# PIC16LF1779 register map
Vendor: Microchip
Registers are 8-bit, read-write, reset 0x0 unless marked. A register's access mark holds for its fields unless they carry their own. Addresses are absolute, and some are shared; only a register's first bit layout is shown; [hi:lo] are bit positions; {n}, {i} and the like mark numbered series; 'fields as' and 'values as' point back to an identical list.

## amp_opamp_hvpump
{0x50B+4i} OPA{i}NCHS (i=1..4)
  [3:0] NCH
{0x50C+4i} OPA{i}PCHS (i=1..4)
  [3:0] PCH
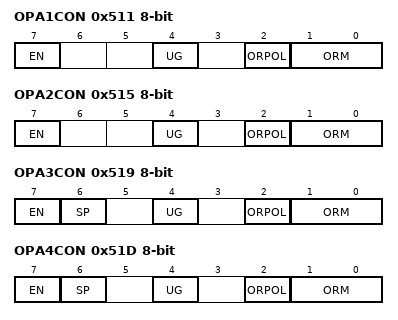
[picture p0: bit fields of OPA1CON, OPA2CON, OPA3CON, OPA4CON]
0x511 OPA1CON
  [7] EN, [4] UG, [2] ORPOL, [1:0] ORM
{0x50E+4i} OPA{i}ORS (i=1..3)
  [4:0] ORS
0x515 OPA2CON
  [7] EN, [4] UG, [2] ORPOL, [1:0] ORM
0x519 OPA3CON
  [7] EN, [6] SP, [4] UG, [2] ORPOL, [1:0] ORM
0x51D OPA4CON
  [7] EN, [6] SP, [4] UG, [2] ORPOL, [1:0] ORM
0x51E OPA4ORS
  [7:0] ORS

## dac_nbit__ctrl
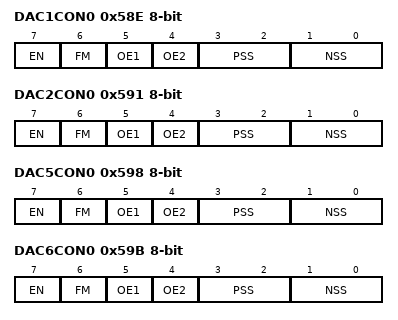
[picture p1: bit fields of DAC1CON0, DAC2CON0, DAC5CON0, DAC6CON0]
0x58E DAC1CON0
  [7] EN, [6] FM, [5] OE1, [4] OE2, [3:2] PSS, [1:0] NSS
0x58F DAC1REFL
  [7:0] REF
0x590 DAC1REFH
  [7:0] REF
0x591 DAC2CON0
  [7] EN, [6] FM, [5] OE1, [4] OE2, [3:2] PSS, [1:0] NSS
0x592 DAC2REFL
  [7:0] REF
0x593 DAC2REFH
  [7:0] REF
0x598 DAC5CON0
  [7] EN, [6] FM, [5] OE1, [4] OE2, [3:2] PSS, [1:0] NSS
0x599 DAC5REFL
  [7:0] REF
0x59A DAC5REFH
  [7:0] REF
0x59B DAC6CON0
  [7] EN, [6] FM, [5] OE1, [4] OE2, [3:2] PSS, [1:0] NSS
0x59C DAC6REFL
  [7:0] REF
0x59D DAC6REFH
  [7:0] REF

## 5bit_DAC_wNSS
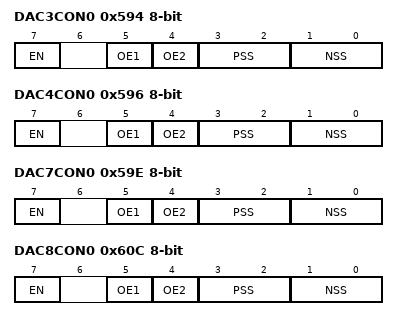
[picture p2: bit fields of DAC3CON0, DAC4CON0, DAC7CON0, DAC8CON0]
0x594 DAC3CON0
  [7] EN, [5] OE1, [4] OE2, [3:2] PSS, [1:0] NSS
0x595 DAC3REF
  [4:0] DACR
0x596 DAC4CON0
  [7] EN, [5] OE1, [4] OE2, [3:2] PSS, [1:0] NSS
0x597 DAC4REF
  [4:0] DACR
0x59E DAC7CON0
  [7] EN, [5] OE1, [4] OE2, [3:2] PSS, [1:0] NSS
0x59F DAC7REF
  [4:0] DACR
0x60C DAC8CON0
  [7] EN, [5] OE1, [4] OE2, [3:2] PSS, [1:0] NSS
0x60D DAC8REF
  [4:0] DACR

## amp_sloperamp_ctrl
0x60E PRG4RTSS
  [3:0] RTSS
0x60F PRG4FTSS
  [3:0] FTSS
0x610 PRG4INS
  [3:0] INS
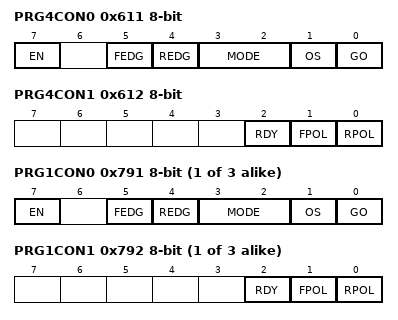
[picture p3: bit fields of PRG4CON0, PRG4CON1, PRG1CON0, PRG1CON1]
0x611 PRG4CON0
  [7] EN, [5] FEDG, [4] REDG, [3:2] MODE, [1] OS, [0] GO
0x612 PRG4CON1
  [2] RDY ro, [1] FPOL, [0] RPOL
0x613 PRG4CON2
  [4:0] ISET
{0x788+6i} PRG{i}RTSS (i=1..3)
  [3:0] RTSS
{0x789+6i} PRG{i}FTSS (i=1..3)
  [3:0] FTSS
{0x78A+6i} PRG{i}INS (i=1..3)
  [3:0] INS
{0x78B+6i} PRG{i}CON0 (i=1..3)
  [7] EN, [5] FEDG, [4] REDG, [3:2] MODE, [1] OS, [0] GO
{0x78C+6i} PRG{i}CON1 (i=1..3)
  [2] RDY ro, [1] FPOL, [0] RPOL
{0x78D+6i} PRG{i}CON2 (i=1..3)
  [4:0] ISET

## pwm_cog
0x68D COG1PHR
  [5:0] PHR
0x68E COG1PHF
  [5:0] PHF
0x68F COG1BLKR
  [5:0] BLKR
0x690 COG1BLKF
  [5:0] BLKF
0x691 COG1DBR
  [5:0] DBR
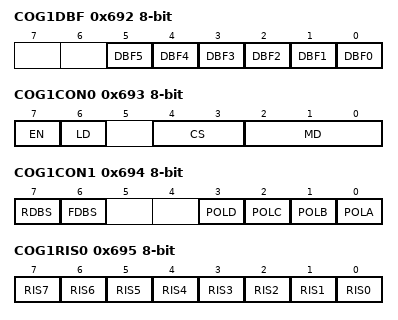
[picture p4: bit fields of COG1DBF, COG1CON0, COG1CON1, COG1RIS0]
0x692 COG1DBF
  [n] DBF{n} (n=0..5)
0x693 COG1CON0
  [7] EN, [6] LD, [4:3] CS, [2:0] MD
0x694 COG1CON1
  [7] RDBS, [6] FDBS, [3] POLD, [2] POLC, [1] POLB, [0] POLA
0x695 COG1RIS0
  [n] RIS{n} (n=0..7)
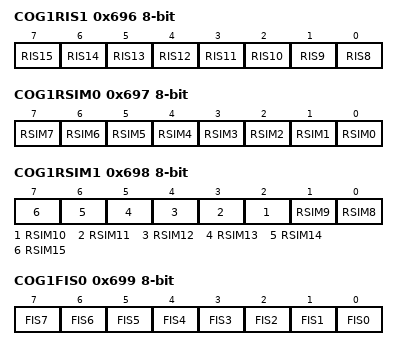
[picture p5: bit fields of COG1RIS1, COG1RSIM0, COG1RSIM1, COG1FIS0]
0x696 COG1RIS1
  [n-8] RIS{n} (n=8..15)
0x697 COG1RSIM0
  [n] RSIM{n} (n=0..7)
0x698 COG1RSIM1
  [n-8] RSIM{n} (n=8..15)
0x699 COG1FIS0
  [n] FIS{n} (n=0..7)
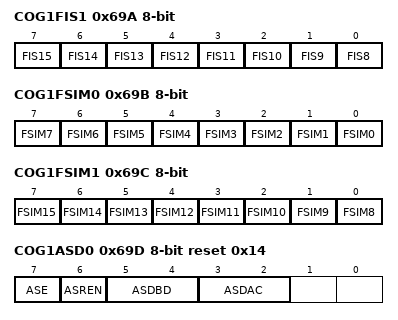
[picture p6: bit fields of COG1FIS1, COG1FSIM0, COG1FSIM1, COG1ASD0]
0x69A COG1FIS1
  [n-8] FIS{n} (n=8..15)
0x69B COG1FSIM0
  [n] FSIM{n} (n=0..7)
0x69C COG1FSIM1
  [n-8] FSIM{n} (n=8..15)
0x69D COG1ASD0 reset 0x14
  [7] ASE, [6] ASREN, [5:4] ASDBD, [3:2] ASDAC
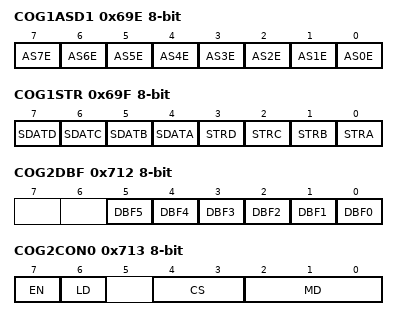
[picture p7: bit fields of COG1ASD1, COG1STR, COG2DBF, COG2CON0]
0x69E COG1ASD1
  [n] AS{n}E (n=0..7)
0x69F COG1STR
  [7] SDATD, [6] SDATC, [5] SDATB, [4] SDATA, [3] STRD, [2] STRC, [1] STRB, [0] STRA
0x70D COG2PHR
  [5:0] PHR
0x70E COG2PHF
  [5:0] PHF
0x70F COG2BLKR
  [5:0] BLKR
0x710 COG2BLKF
  [5:0] BLKF
0x711 COG2DBR
  [5:0] DBR
0x712 COG2DBF
  [n] DBF{n} (n=0..5)
0x713 COG2CON0
  [7] EN, [6] LD, [4:3] CS, [2:0] MD
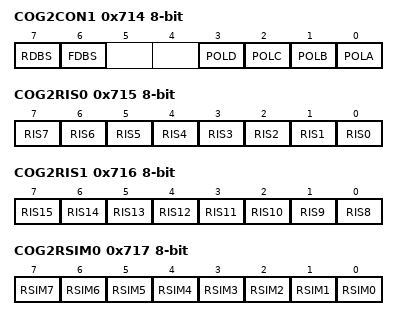
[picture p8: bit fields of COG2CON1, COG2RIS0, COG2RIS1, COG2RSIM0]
0x714 COG2CON1
  [7] RDBS, [6] FDBS, [3] POLD, [2] POLC, [1] POLB, [0] POLA
0x715 COG2RIS0
  [n] RIS{n} (n=0..7)
0x716 COG2RIS1
  [n-8] RIS{n} (n=8..15)
0x717 COG2RSIM0
  [n] RSIM{n} (n=0..7)
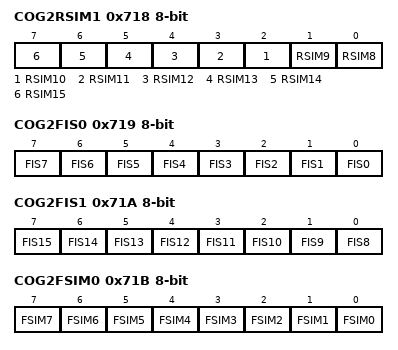
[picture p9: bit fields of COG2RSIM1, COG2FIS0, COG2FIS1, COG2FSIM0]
0x718 COG2RSIM1
  [n-8] RSIM{n} (n=8..15)
0x719 COG2FIS0
  [n] FIS{n} (n=0..7)
0x71A COG2FIS1
  [n-8] FIS{n} (n=8..15)
0x71B COG2FSIM0
  [n] FSIM{n} (n=0..7)
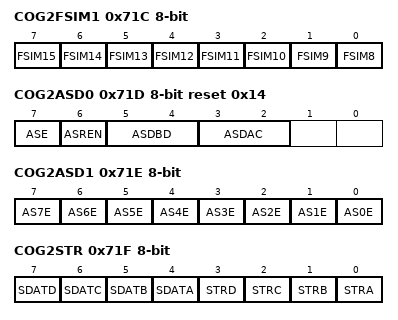
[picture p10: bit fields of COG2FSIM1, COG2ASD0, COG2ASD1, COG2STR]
0x71C COG2FSIM1
  [n-8] FSIM{n} (n=8..15)
0x71D COG2ASD0 reset 0x14
  [7] ASE, [6] ASREN, [5:4] ASDBD, [3:2] ASDAC
0x71E COG2ASD1
  [n] AS{n}E (n=0..7)
0x71F COG2STR
  fields as COG1STR
0x80D COG3PHR
  [5:0] PHR
0x80E COG3PHF
  [5:0] PHF
0x80F COG3BLKR
  [5:0] BLKR
0x810 COG3BLKF
  [5:0] BLKF
0x811 COG3DBR
  [5:0] DBR
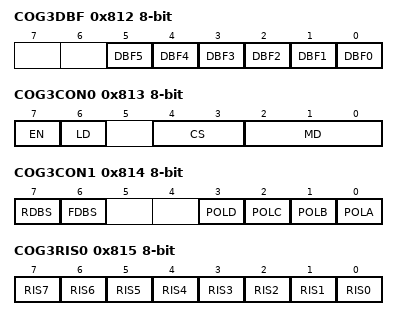
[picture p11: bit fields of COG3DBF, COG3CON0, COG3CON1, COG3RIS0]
0x812 COG3DBF
  [n] DBF{n} (n=0..5)
0x813 COG3CON0
  [7] EN, [6] LD, [4:3] CS, [2:0] MD
0x814 COG3CON1
  [7] RDBS, [6] FDBS, [3] POLD, [2] POLC, [1] POLB, [0] POLA
0x815 COG3RIS0
  [n] RIS{n} (n=0..7)
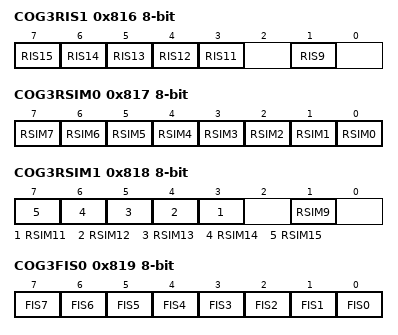
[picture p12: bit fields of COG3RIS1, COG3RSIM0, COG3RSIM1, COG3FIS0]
0x816 COG3RIS1
  [n-8] RIS{n} (n=11..15), [1] RIS9
0x817 COG3RSIM0
  [n] RSIM{n} (n=0..7)
0x818 COG3RSIM1
  [n-8] RSIM{n} (n=11..15), [1] RSIM9
0x819 COG3FIS0
  [n] FIS{n} (n=0..7)
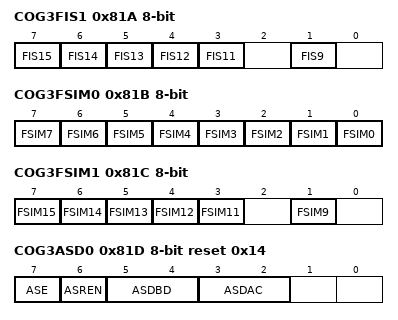
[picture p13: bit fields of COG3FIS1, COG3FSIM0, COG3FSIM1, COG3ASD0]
0x81A COG3FIS1
  [n-8] FIS{n} (n=11..15), [1] FIS9
0x81B COG3FSIM0
  [n] FSIM{n} (n=0..7)
0x81C COG3FSIM1
  [n-8] FSIM{n} (n=11..15), [1] FSIM9
0x81D COG3ASD0 reset 0x14
  [7] ASE, [6] ASREN, [5:4] ASDBD, [3:2] ASDAC
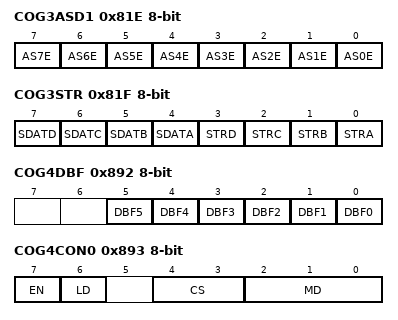
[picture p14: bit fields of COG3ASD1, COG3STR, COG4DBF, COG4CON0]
0x81E COG3ASD1
  [n] AS{n}E (n=0..7)
0x81F COG3STR
  fields as COG1STR
0x88D COG4PHR
  [5:0] PHR
0x88E COG4PHF
  [5:0] PHF
0x88F COG4BLKR
  [5:0] BLKR
0x890 COG4BLKF
  [5:0] BLKF
0x891 COG4DBR
  [5:0] DBR
0x892 COG4DBF
  [n] DBF{n} (n=0..5)
0x893 COG4CON0
  [7] EN, [6] LD, [4:3] CS, [2:0] MD
0x894 COG4CON1
  [7] RDBS, [6] FDBS, [3] POLD, [2] POLC, [1] POLB, [0] POLA
0x895 COG4RIS0
  [n] RIS{n} (n=0..7)
0x896 COG4RIS1
  [n-8] RIS{n} (n=8..15)
0x897 COG4RSIM0
  [n] RSIM{n} (n=0..7)
0x898 COG4RSIM1
  [n-8] RSIM{n} (n=8..15)
0x899 COG4FIS0
  [n] FIS{n} (n=0..7)
0x89A COG4FIS1
  [n-8] FIS{n} (n=8..15)
0x89B COG4FSIM0
  [n] FSIM{n} (n=0..7)
0x89C COG4FSIM1
  [n-8] FSIM{n} (n=8..15)
0x89D COG4ASD0 reset 0x14
  [7] ASE, [6] ASREN, [5:4] ASDBD, [3:2] ASDAC
0x89E COG4ASD1
  [n] AS{n}E (n=0..7)
0x89F COG4STR
  fields as COG1STR

## CLC
{0xF06+0xA*i} CLC{i}CON (i=1..4) — Configurable logic cell control
  [7] LC{i}EN, [5] LC{i}OUT ro, [4] LC{i}INTP, [3] LC{i}INTN, [2:0] LC{i}MODE
{0xF07+0xA*i} CLC{i}POL reset not defined (i=1..4) — Polarity control (power-on value 0---xxxx)
  [7] LC{i}POL, [n-1] LC{i}G{n}POL (n=1..4)
{0xF08+0xA*i} CLC{i}SEL0 reset not defined (i=1..4) — Input select register 1 (power-on value --xxxxxx)
  [n] LC{i}D1S{n} (n=0..5)
{0xF09+0xA*i} CLC{i}SEL1 reset not defined (i=1..4) — Input select register 1 (power-on value --xxxxxx)
  [n] LC{i}D2S{n} (n=0..5)
{0xF0A+0xA*i} CLC{i}SEL2 reset not defined (i=1..4) — Input select register 2 (power-on value --xxxxxx)
  [n] LC{i}D3S{n} (n=0..5)
{0xF0B+0xA*i} CLC{i}SEL3 reset not defined (i=1..4) — Input select register 3 (power-on value --xxxxxx)
  [n] LC{i}D4S{n} (n=0..5)
{0xF0C+0xA*i} CLC{i}GLS0 reset not defined (i=1..4) — Gate logic select register 0 (power-on value xxxxxxxx)
  [2n-1] LC{i}G1D{n}T (n=1..4), [2n-2] LC{i}G1D{n}N (n=1..4)
{0xF0D+0xA*i} CLC{i}GLS1 reset not defined (i=1..4) — Gate logic select register 1 (power-on value xxxxxxxx)
  [2n-1] LC{i}G2D{n}T (n=1..4), [2n-2] LC{i}G2D{n}N (n=1..4)
{0xF0E+0xA*i} CLC{i}GLS2 reset not defined (i=1..4) — Gate logic select register 2 (power-on value xxxxxxxx)
  [2n-1] LC{i}G3D{n}T (n=1..4), [2n-2] LC{i}G3D{n}N (n=1..4)
{0xF0F+0xA*i} CLC{i}GLS3 reset not defined (i=1..4) — Gate logic select register 3 (power-on value xxxxxxxx)
  [2n-1] LC{i}G4D{n}T (n=1..4), [2n-2] LC{i}G4D{n}N (n=1..4)
